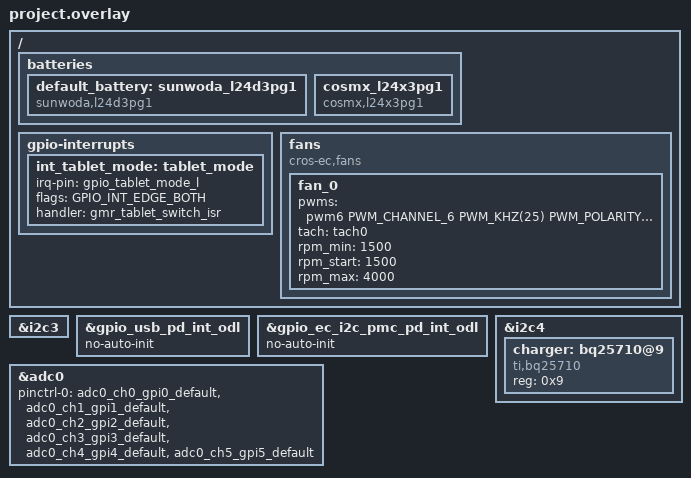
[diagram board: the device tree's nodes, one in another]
/* Copyright 2024 The ChromiumOS Authors
 * Use of this source code is governed by a BSD-style license that can be
 * found in the LICENSE file.
 */

/* Brox program common DTS includes */

/* Arbitrage generates an incorrect node label when using alternate pins.
 * Create a 2nd node label on I2C3 as a workaround.
 * TODO: b/310227384 - I2C alternate selection not detected automatically.
 */
 i2c3ALT: &i2c3 {
};

#include <cros/cbi_flash.dtsi>

#include "../binman.dtsi"
#include "../brox.dtsi"
#include "../fan.dtsi"
#include "gpio.dtsi"
#include "../i2c.dtsi"
#include "../interrupts.dtsi"
#include "../motionsense.dtsi"
#include "../power_signals.dtsi"
#include "../power_signals_gpios.dtsi"
#include "../pwm.dtsi"
#include "../usb_typec.dtsi"
#include "../usba.dtsi"

/* Lotso project DTS includes*/
#include "alt_motionsense.dtsi"
#include "cbi.dtsi"
#include "keyboard.dtsi"
#include "led_pins.dtsi"
#include "led_policy.dtsi"
#include "temp_sensors.dtsi"

/* Lotso overrides follow... */

/{
        batteries {
		default_battery: sunwoda_l24d3pg1 {
			compatible = "sunwoda,l24d3pg1", "battery-smart";
		};
		cosmx_l24x3pg1 {
			compatible = "cosmx,l24x3pg1", "battery-smart";
		};
        };

        gpio-interrupts {
                /delete-node/ volume_up;
                /delete-node/ volume_down;

		int_tablet_mode: tablet_mode {
			irq-pin = <&gpio_tablet_mode_l>;
			flags = <GPIO_INT_EDGE_BOTH>;
			handler = "gmr_tablet_switch_isr";
		};
        };

	fans {
		compatible = "cros-ec,fans";
		fan_0 {
			pwms = <&pwm6 PWM_CHANNEL_6
				PWM_KHZ(25)
				PWM_POLARITY_NORMAL>;
			tach = <&tach0>;
			rpm_min = <1500>;
			rpm_start = <1500>;
			rpm_max = <4000>;
		};
	};
};

/* These GPIOS are initialized by the PDC driver */
&gpio_usb_pd_int_odl {
	no-auto-init;
};
&gpio_ec_i2c_pmc_pd_int_odl {
	no-auto-init;
};

&i2c4 {
	/delete-node/ isl9238@9;

        charger: bq25710@9 {
		compatible = "ti,bq25710";
		status = "okay";
		reg = <0x9>;
	};
};

&adc0 {
	pinctrl-0 = <&adc0_ch0_gpi0_default
		     &adc0_ch1_gpi1_default
		     &adc0_ch2_gpi2_default
		     &adc0_ch3_gpi3_default
		     &adc0_ch4_gpi4_default
		     &adc0_ch5_gpi5_default>;
	pinctrl-names = "default";
};
